# STM32U5A5xx register map
File version: 1.0
Registers are 32-bit, read-write, reset 0x0 unless marked. A register's access mark holds for its fields unless they carry their own. Offsets are from the block's base; [hi:lo] are bit positions; lines under a group give offsets from that group; {n}, {i} and the like mark numbered series.

## ADC12_COMMON
Base 0x42028300
Same registers: ADC12_COMMON_S 0x52028300
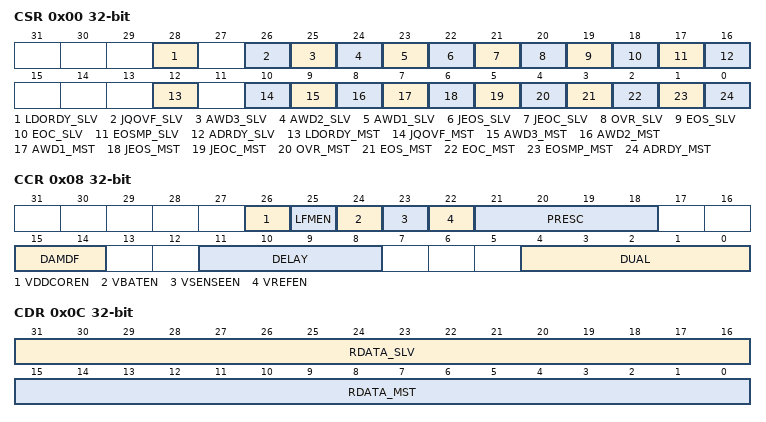
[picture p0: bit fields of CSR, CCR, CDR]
0x00 CSR — ADC common status register
  [28] LDORDY_SLV — Voltage regulator ready flag of the slave ADC
  [26] JQOVF_SLV — Injected context queue overflow flag of the slave ADC
  [25] AWD3_SLV — Analog watchdog 3 flag of the slave ADC
  [24] AWD2_SLV — Analog watchdog 2 flag of the slave ADC
  [23] AWD1_SLV — Analog watchdog 1 flag of the slave ADC
  [22] JEOS_SLV — End of injected sequence flag of the slave ADC
  [21] JEOC_SLV — End of injected conversion of the slave ADC
  [20] OVR_SLV — Overrun flag of the slave ADC
  [19] EOS_SLV — End of regular sequence flag of the slave ADC
  [18] EOC_SLV — End of regular conversion of the slave ADC
  [17] EOSMP_SLV — End of sampling phase flag of the slave ADC
  [16] ADRDY_SLV — Slave ADC ready
  [12] LDORDY_MST — Voltage regulator ready flag of the master ADC
  [10] JQOVF_MST — Injected context queue overflow flag of the master ADC
  [9] AWD3_MST — Analog watchdog 3 flag of the master ADC
  [8] AWD2_MST — Analog watchdog 2 flag of the master ADC
  [7] AWD1_MST — Analog watchdog 1 flag of the master ADC
  [6] JEOS_MST — End of injected sequence flag of the master ADC
  [5] JEOC_MST — End of injected conversion of the master ADC
  [4] OVR_MST — Overrun flag of the master ADC
  [3] EOS_MST — End of regular sequence flag of the master ADC
  [2] EOC_MST — End of regular conversion of the master ADC
  [1] EOSMP_MST — End of sampling phase flag of the master ADC
  [0] ADRDY_MST — Master ADC ready
0x08 CCR — ADC common control register
  [26] VDDCOREN — VDDCode enable
  [25] LFMEN — Low Frequency Mode Enable, specific ADC4
  [24] VBATEN — VBAT enable
  [23] VSENSEEN — Temperature sensor enable
  [22] VREFEN — VREFINT enable
  [21:18] PRESC — ADC prescaler
    0=DIV1; 1=DIV2; 2=DIV4; 3=DIV6; 4=DIV8; 5=DIV10; 6=DIV12; 7=DIV16; 8=DIV32; 9=DIV64; 10=DIV128; 11=DIV256
  [15:14] DAMDF — Dual ADC mode data format
    0=EACH_ADC (ADC multimode group regular conversions are transferred by DMA: each ADC uses its own DMA channel, with its individual DMA transfer settings); 2=RES_32_10B (ADC multimode group regular conversions are transferred by DMA, one DMA channel for both ADC (DMA of ADC master). Setting for ADC resolution of 32 (16x2) down to 10 bits); 3=RES_8B (ADC multimode group regular conversions are transferred by DMA, one DMA channel for both ADC (DMA of ADC master). Setting for ADC resolution of 8 bits)
  [11:8] DELAY — Delay between 2 sampling phases
    0=DELAY_1CYCLE (ADC multimode delay between two sampling phases: 1 ADC clock cycle for all resolution); {v}=DELAY_{v+1}CYCLES (ADC multimode delay between two sampling phases: {v+1} ADC clock cycles for all resolution) (v=1..14); 15=DELAY_13CYCLES_8_BITS (ADC multimode delay between two sampling phases: 13 ADC clock cycles for 8 bits resolution)
  [4:0] DUAL — Dual ADC mode selection
    0=INDEPENDENT (ADC dual mode disabled (ADC independent mode)); 6=DUAL_REG_SIMULT (ADC dual mode enabled: group regular simultaneous); 7=DUAL_REG_INTERL (ADC dual mode enabled: Combined group regular interleaved); 5=DUAL_INJ_SIMULT (ADC dual mode enabled: group injected simultaneous); 9=DUAL_INJ_ALTERN (ADC dual mode enabled: group injected alternate trigger. Works only with external triggers (not internal SW start)); 1=DUAL_REG_SIM_INJ_SIM (ADC dual mode enabled: Combined group regular simultaneous + group injected simultaneous); 2=DUAL_REG_SIM_INJ_ALT (ADC dual mode enabled: Combined group regular simultaneous + group injected alternate trigger); 3=DUAL_REG_INT_INJ_SIM (ADC dual mode enabled: Combined group regular interleaved + group injected simultaneous)
0x0C CDR — ADC common regular data register for dual mode
  [31:16] RDATA_SLV — ADC multimode slave group regular conversion data
  [15:0] RDATA_MST — ADC multimode master group regular conversion data
0x10 CDR2 — ADC common regular data register for 32-bit dual mode
  [31:0] RDATA_ALT — Regular data of the master/slave alternated ADCs
